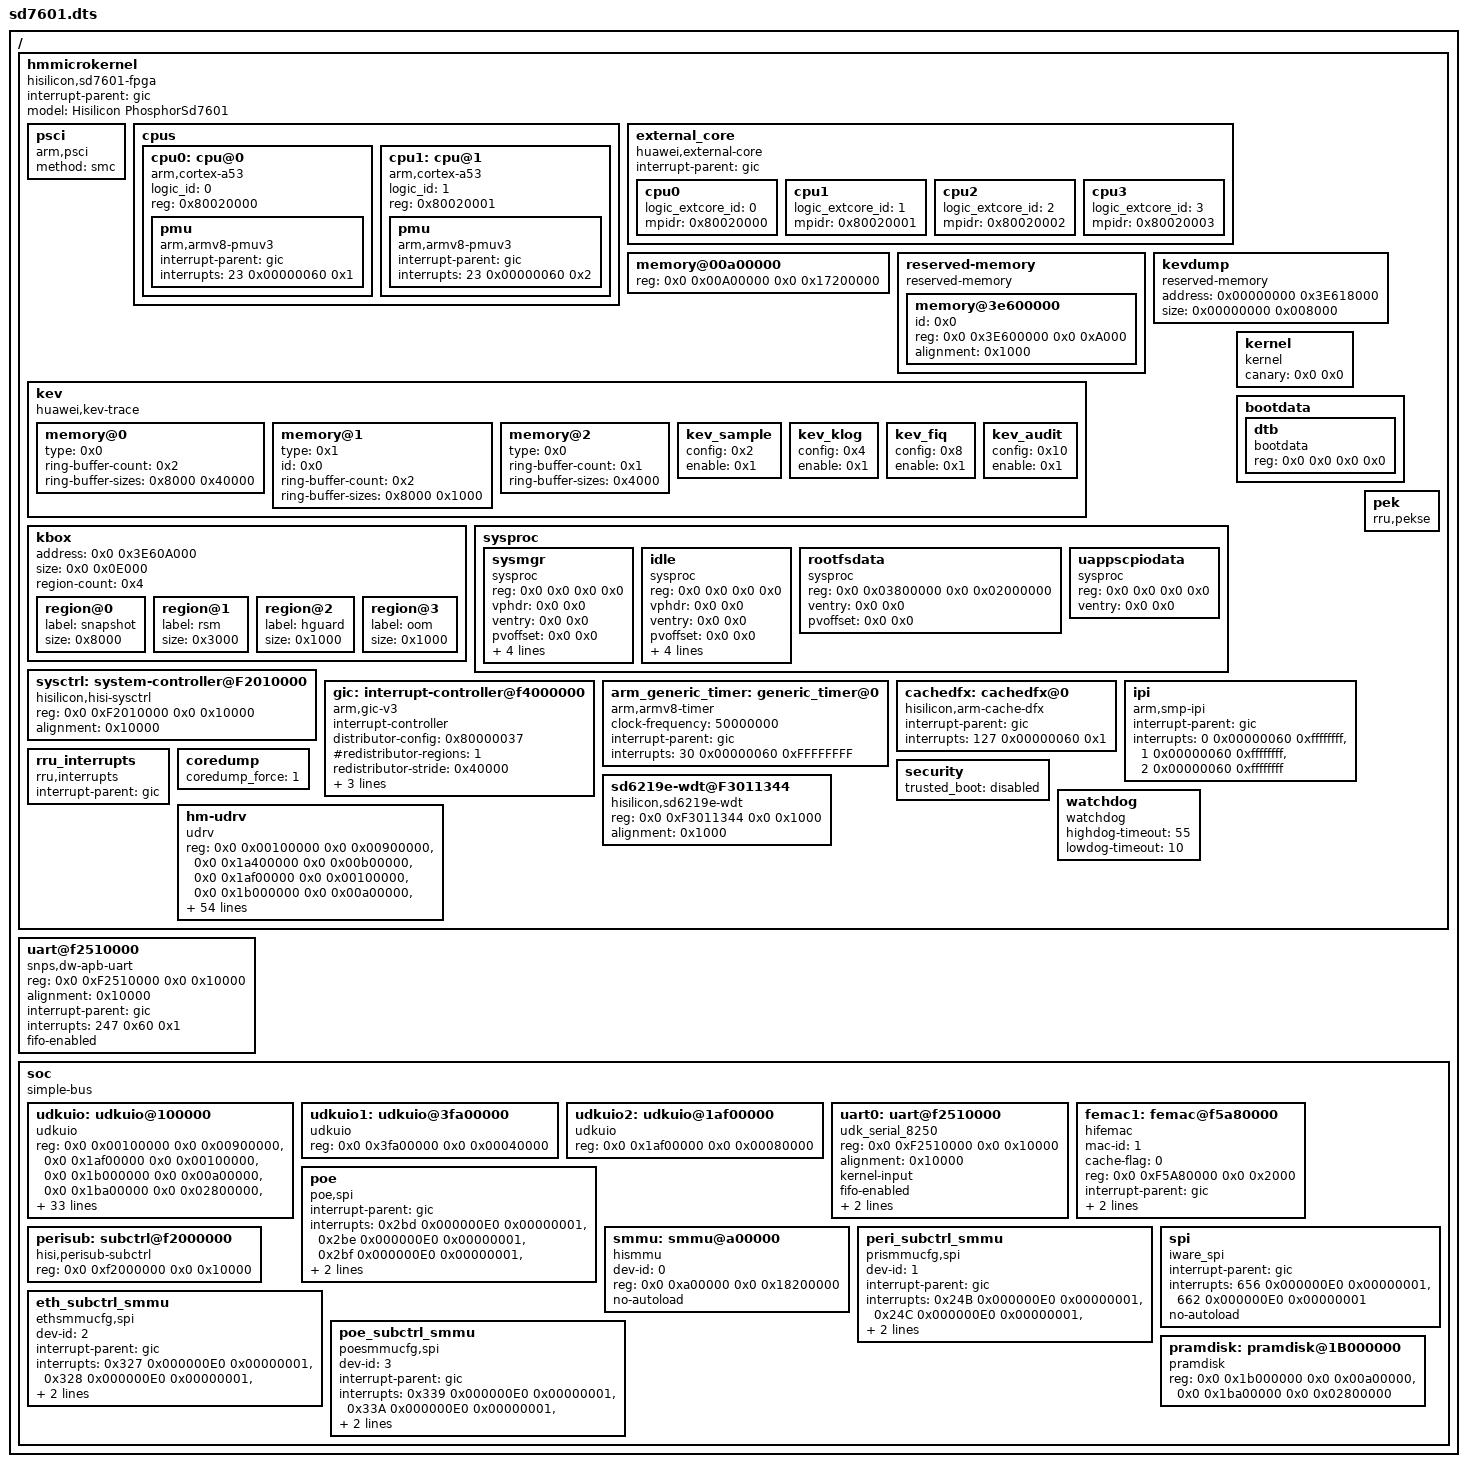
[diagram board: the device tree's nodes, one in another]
/*
 * Copyright (c) Huawei Technologies Co., Ltd. 2020-2021. All rights reserved.
 * Description: Device Tree file for TIANSHAN SD7601 BBL Board
 * Author: Huawei OS Kernel Lab
 * Create: Thu Sep 13 03:39:49 2020
 */

/dts-v1/;

/ {
	#address-cells = <2>;
	#size-cells = <2>;
	hmmicrokernel {
		#address-cells = <2>;
		#size-cells = <2>;
		interrupt-parent = <&gic>;

		model = "Hisilicon PhosphorSd7601";
		compatible = "hisilicon,sd7601-fpga", "hisilicon,hisi-sd7601";

		psci {
			compatible = "arm,psci";
			method = "smc";
		};

		cpus {
			#address-cells = <1>;
			#size-cells = <0>;

			cpu0: cpu@0 {
				compatible = "arm,cortex-a53", "arm,armv8";
				device_type = "cpu";
				logic_id = <0>;
				reg = <0x80020000>;
				pmu {
					compatible = "arm,armv8-pmuv3";
					interrupt-parent = <&gic>;
					/* PPI 23: PMUIRQ, level triggered, hwprio:0x60 */
					interrupts = <23 0x00000060 0x1>;
				};
			};
			cpu1: cpu@1 {
				compatible = "arm,cortex-a53", "arm,armv8";
				device_type = "cpu";
				logic_id = <1>;
				reg = <0x80020001>;
				pmu {
					compatible = "arm,armv8-pmuv3";
					interrupt-parent = <&gic>;
					/* PPI 23: PMUIRQ, level triggered, hwprio:0x60 */
					interrupts = <23 0x00000060 0x2>;
				};
			};
		};

		external_core {
			compatible = "huawei,external-core";

			interrupt-parent = <&gic>;

			cpu0 {
				logic_extcore_id = <0>;
				mpidr = <0x80020000>;
			};
			cpu1 {
				logic_extcore_id = <1>;
				mpidr = <0x80020001>;
			};
			cpu2 {
				logic_extcore_id = <2>;
				mpidr = <0x80020002>;
			};
			cpu3 {
				logic_extcore_id = <3>;
				mpidr = <0x80020003>;
			};
		};

		memory@00a00000 {
			device_type = "memory";
			reg = <0x0 0x00A00000 0x0 0x17200000>; /* OS kernel */
		};

		/* reserved memory for kev uses 0x3E600000-0x3E60A000 */
		reserved-memory {
			compatible = "reserved-memory";
			#address-cells = <2>;
			#size-cells = <2>;
			memory@3e600000 {
				id = <0x0>;
				reg = <0x0 0x3E600000 0x0 0xA000>;
				alignment = <0x1000>;
			};
		};

		/* kev uses 0x3E600000-0x3E60A000 */
		kev {
			compatible = "huawei,kev-trace";

			memory@0 {
				type = <0x0>;
				ring-buffer-count = <0x2>;
				/*
				 * ring buffer 0: 32K
				 * ring buffer 1: 256K
				 */
				ring-buffer-sizes = <0x8000 0x40000>;
			};

			memory@1 {
				type = <0x1>; /* reserved memory */
				id = <0x0>;
				ring-buffer-count = <0x2>;
				/*
				 * Only ring buffer DATA sizes. Memory head and ring
				 * buffer heads are not included.
				 * ring buffer 2: 32K(klog)
				 * ring buffer 3: 4K(fiq)
				 */
				ring-buffer-sizes = <0x8000 0x1000>;
			};

			memory@2 {
				type = <0x0>;
				ring-buffer-count = <0x1>;
				/*
				 * ring buffer 4: 16K(audit)
				 */
				ring-buffer-sizes = <0x4000>;
			};
			kev_sample {
				config = <0x2>;
				enable = <0x1>;
			};
			kev_klog {
				config = <0x4>;
				enable = <0x1>;
			};
			kev_fiq {
				config = <0x8>;
				enable = <0x1>;
			};
			kev_audit {
				config = <0x10>;
				enable = <0x1>;
			};
		};

		/* kbox uses 0x3E60A000-0x3E618000 */
		kbox {
			address = <0x0 0x3E60A000>;
			size = <0x0 0x0E000>;
			region-count= <0x4>;
			region@0 {
				label = "snapshot";
				size = <0x8000>;
			};
			region@1 {
				label = "rsm";
				size = <0x3000>;
			};
			region@2 {
				label = "hguard";
				size = <0x1000>;
			};
			region@3 {
				label = "oom";
				size = <0x1000>;
			};
		};

		/* kevdump uses 0x3E618000-0x3E620000 */
		kevdump {
			compatible = "reserved-memory";
			address = <0x00000000 0x3E618000>;
			size = <0x00000000 0x008000>;
		};

		sysproc {
			#address-cells = <2>;
			#size-cells = <2>;
			sysmgr {
				compatible = "sysproc", "sysmgr";
				/* filled by bootloader */
				reg      = <0x0 0x0 0x0 0x0>;
				vphdr    = <0x0 0x0>;
				ventry   = <0x0 0x0>;
				pvoffset = <0x0 0x0>;
				nphdrs   = <0>;
				stack_start = <0x0 0x0>;
				stack_end = <0x0 0x0>;
				canary = <0x0 0x0>;
			};
			idle {
				compatible = "sysproc", "idle";
				/* filled by bootloader */
				reg      = <0x0 0x0 0x0 0x0>;
				vphdr    = <0x0 0x0>;
				ventry   = <0x0 0x0>;
				pvoffset = <0x0 0x0>;
				nphdrs   = <0>;
				stack_start = <0x0 0x0>;
				stack_end = <0x0 0x0>;
				canary = <0x0 0x0>;
			};
			/* Describe board boot param rootfs in top level dts */
			rootfsdata {
				compatible = "sysproc", "rootfs";
				reg = <0x0 0x03800000 0x0 0x02000000>;
				ventry = <0x0 0x0>;
				/* filled by bootloader */
				pvoffset = <0x0 0x0>;
			};
			/*
			 * Describe uappscpio param in dts, which will be edited by elfloader_ng
			 * after uapps.cpio is loaded, provide for loading uapps
			 */
			uappscpiodata {
				compatible = "sysproc", "uappscpio";
				/* filled by bootloader */
				reg      = <0x0 0x0 0x0 0x0>;
				ventry   = <0x0 0x0>;
			};
		};

		kernel {
			compatible = "kernel";
			/* filled by bootloader */
			canary = <0x0 0x0>;
		};

		bootdata {
			#address-cells = <2>;
			#size-cells = <2>;
			dtb {
				compatible = "bootdata", "dtb";
				/* filled by bootloader */
				reg = <0x0 0x0 0x0 0x0>;
			};
		};

		sysctrl: system-controller@F2010000 {
			compatible = "hisilicon,hisi-sysctrl", "syscon";
			reg = <0x0 0xF2010000 0x0 0x10000>;
			alignment = <0x10000>;
		};

		gic: interrupt-controller@f4000000 {
			compatible = "arm,gic-v3";
			#interrupt-cells = <3>;
			interrupt-controller;

			/* Enable group 0, Group1NS, Group1S, ARE_NS, ARE_S,
			 * Split EOI and Deactive Mode */
			distributor-config = <0x80000037>;

			#redistributor-regions = <1>;
			redistributor-stride = <0x40000>;

			reg = <0x0 0xF4000000 0x0 0x10000>,  /* GICD */
			      <0x0 0xF4100000 0x0 0x400000>; /* GICR 16 CORE */
			alignment = <0x1000 0x1000>;
		};

		arm_generic_timer: generic_timer@0 {
			compatible = "arm,armv8-timer";
			clock-frequency = <50000000>;

			/* interrupt settings */
			interrupt-parent = <&gic>;

			/* PPI 30: Non-secure physical timer
			 * level triggered, hwprio:60 */
			interrupts = <30 0x00000060 0xFFFFFFFF>;
		};

		cachedfx: cachedfx@0 {
			compatible = "hisilicon,arm-cache-dfx";
			interrupt-parent = <&gic>;
			interrupts = <127 0x00000060 0x1>;
		};

		ipi {
			/* smp ipi */
			compatible = "arm,smp-ipi";

			interrupt-parent = <&gic>;

			/* interrupt settings:
			 * 1st cell: real hardware irq number
			 *     ARM recommendation: ID 0-7 for Non-Secure;
			 *                         ID 8-15 for Secure Interrupt
			 * 2nd cell: interrupt config
			 *     bit [27:26]: Group setting
			 *     bit [24]: Trigger Type
			 *     bit [23:8]: reserved
			 *     bit [7:0]: Priority
			 * 3rd cell: interrupt target config
			 *     support a maximum 8 CPUs.
			 */
			interrupts = <0 0x00000060 0xffffffff>, /* IPI_RESCHEDULE */
				     <1 0x00000060 0xffffffff>, /* IPI_CALL_FUNC */
				     <2 0x00000060 0xffffffff>; /* IPI_CPU_STOP */
		};

		/* using user-level irq dispatcher to manage all rru irqs */
		rru_interrupts {
			compatible = "rru,interrupts";
			interrupt-parent = <&gic>;
		};

		coredump {
			coredump_force = <1>;
		};
		security {
			trusted_boot = "disabled";
		};

		/* SD7601 CPU use same watchdog as sd6219e */
		sd6219e-wdt@F3011344 {
			compatible = "hisilicon,sd6219e-wdt";
			#address-cells = <2>;
			#size-cells = <2>;

			reg = <0x0 0xF3011344 0x0 0x1000>;
			alignment = <0x1000>;
		};

		watchdog {
			compatible = "watchdog";
			/* reserve 55ms for hguard to take over the watchdog */
			highdog-timeout = <55>;
			/* reserve 10ms for subcore to be pulled up*/
			lowdog-timeout = <10>;
		};

		hm-udrv {
			compatible = "udrv";
			reg = <0x0 0x00100000 0x0 0x00900000>, /* udkuio */
			      <0x0 0x1a400000 0x0 0x00b00000>, /* tee drv */
			      <0x0 0x1af00000 0x0 0x00100000>, /* libteec trace */
			      <0x0 0x1b000000 0x0 0x00a00000>, /* pramdisk idump*/
			      <0x0 0x1ba00000 0x0 0x02800000>, /* pramdisk lplog*/
			      <0x0 0x1e200000 0x0 0x00200000>, /* peklog */
			      <0x0 0x20400000 0x0 0x00400000>, /* femac + smmu */
			      <0x0 0x2da00000 0x0 0x0e800000>, /* udkuio */
			      <0x0 0x3c400000 0x0 0x00400000>, /* acc */
			      <0x0 0x3ce00000 0x0 0x00a00000>, /* udkuio */
			      <0x0 0x3d800000 0x0 0x00400000>, /* udkuio */
			      <0x0 0x3e200000 0x0 0x01e00000>, /* kbox */
			      <0x0 0x60000000 0x0 0x00004000>, /* udkuio */
			      <0x0 0xc0000000 0x0 0x20000000>, /* udkuio */
			      <0x0 0xf1000000 0x0 0x00100000>, /* udkuio */
			      <0x0 0xf12a0000 0x0 0x00001000>, /* udkuio */
			      <0x0 0xf1702000 0x0 0x00001000>, /* i2c */
			      <0x0 0xf1310000 0x0 0x00001000>, /* udkuio */
			      <0x0 0xf2000000 0x0 0x00100000>, /* spi, espi */
			      <0x0 0xf2140000 0x0 0x00240000>, /* udkuio */
			      <0x0 0xf23e0000 0x0 0x00040000>, /* i2c */
			      <0x0 0xf2400000 0x0 0x00001000>,
			      <0x0 0xf2410000 0x0 0x00001000>,
			      <0x0 0xf2430000 0x0 0x00020000>, /* spi */
			      <0x0 0xf2490000 0x0 0x00010000>, /* nor */
			      <0x0 0xf24a0000 0x0 0x00010000>, /* trng */
			      <0x0 0xf24e0000 0x0 0x00010000>, /* espi */
			      <0x0 0xf2510000 0x0 0x00010000>, /* uart */
			      <0x0 0xf2520000 0x0 0x00001000>,
			      <0x0 0xf2540000 0x0 0x00040000>, /* udkuio */
			      <0x0 0xf2548000 0x0 0x00001000>, /* gpio */
			      <0x0 0xf2558000 0x0 0x00001000>,
			      <0x0 0xf2568000 0x0 0x00001000>,
			      <0x0 0xf2578000 0x0 0x00001000>,
			      <0x0 0xf2588000 0x0 0x00001000>,
			      <0x0 0xf2598000 0x0 0x00001000>,
			      <0x0 0xf25A8000 0x0 0x00001000>,
			      <0x0 0xf25B8000 0x0 0x00001000>, /* gpio */
			      <0x0 0xf2700000 0x0 0x00024000>,
			      <0x0 0xf3000000 0x0 0x00100000>, /* spi */
			      <0x0 0xf5000000 0x0 0x00100000>, /* udkuio */
			      <0x0 0xf5200000 0x0 0x00020000>, /* udkuio */
			      <0x0 0xf5880000 0x0 0x00003000>,
			      <0x0 0xf5A80000 0x0 0x00002000>, /* femac0 */
			      <0x0 0xf5b80000 0x0 0x00010000>, /* spi */
			      <0x0 0xf5c00000 0x0 0x00010000>, /* spi */
			      <0x0 0xf7000000 0x0 0x00100000>, /* udkuio */
			      <0x0 0xfa000000 0x0 0x00b00000>, /* udkuio */
			      <0x0 0xfb000000 0x0 0x00a00000>, /* udkuio */
			      <0x0 0xfc000000 0x0 0x00100000>, /* espi */
			      <0x0 0xfd000000 0x0 0x01400000>, /* udkuio */
			      <0x0 0xfe400000 0x0 0x00400000>, /* udkuio */
			      <0x0 0xfe800000 0x0 0x00100000>, /* udkuio */
			      <0x0 0xff000000 0x0 0x01000000>, /* udkuio */
			      <0x6 0x00000000 0x0 0x10000000>, /* espi, SFC */
			      <0x6 0xc0000000 0x1 0x40000000>, /* SRE CP PA */
			      <0xA 0x01000000 0x0 0x02000000>,
			      <0xA 0x04000000 0x0 0x02000000>;
		};

		pek {
			compatible = "rru,pekse";
		};
	};

	/* For kernel uart driver */
	uart@f2510000 {
		compatible = "snps,dw-apb-uart", "arm,dw8250,uart";
		reg = <0x0 0xF2510000 0x0 0x10000>;
		alignment = <0x10000>;

		interrupt-parent = <&gic>;
		/* priority 2, level-triggered, target cpu 0 */
		interrupts = <247 0x60 0x1>;
		/* enable fifo */
		fifo-enabled;
	};

	soc {
		compatible = "simple-bus";
		#address-cells = <2>;
		#size-cells = <2>;
		ranges;

		udkuio: udkuio@100000 {
			compatible = "udkuio";
			reg = <0x0 0x00100000 0x0 0x00900000>,
			      <0x0 0x1af00000 0x0 0x00100000>,
			      <0x0 0x1b000000 0x0 0x00a00000>, /* pramdisk idump*/
			      <0x0 0x1ba00000 0x0 0x02800000>, /* pramdisk lplog*/
			      <0x0 0x1e200000 0x0 0x00200000>, /* peklog */
			      <0x0 0x20400000 0x0 0x00400000>, /* femac + smmu */
			      <0x0 0x2da00000 0x0 0x0e800000>,
			      <0x0 0x3ce00000 0x0 0x00a00000>,
			      <0x0 0x3d800000 0x0 0x00400000>,
			      <0x0 0x3e200000 0x0 0x01e00000>, /* kbox */
			      <0x0 0x60000000 0x0 0x00004000>,
			      <0x0 0xc0000000 0x0 0x20000000>,
			      <0x0 0xf1000000 0x0 0x00100000>,
			      <0x0 0xf12a0000 0x0 0x00001000>,
			      <0x0 0xf1310000 0x0 0x00001000>,
			      <0x0 0xf2000000 0x0 0x00100000>,
			      <0x0 0xf2140000 0x0 0x00240000>,
			      <0x0 0xf24a0000 0x0 0x00010000>, /* trng */
			      <0x0 0xf24e0000 0x0 0x00010000>, /* espi */
			      <0x0 0xf2540000 0x0 0x00040000>,
			      <0x0 0xf3000000 0x0 0x00100000>,
			      <0x0 0xf5000000 0x0 0x00100000>,
			      <0x0 0xf5200000 0x0 0x00020000>,
			      <0x0 0xf7000000 0x0 0x00100000>,
			      <0x0 0xfa000000 0x0 0x00b00000>,
			      <0x0 0xfb000000 0x0 0x00a00000>,
			      <0x0 0xfc000000 0x0 0x00100000>,
			      <0x0 0xfd000000 0x0 0x01400000>,
			      <0x0 0xfe400000 0x0 0x00400000>,
			      <0x0 0xfe800000 0x0 0x00100000>,
			      <0x0 0xff000000 0x0 0x01000000>,
			      <0x6 0x00000000 0x0 0x01000000>, /* espi, SFC */
			      <0x6 0x01000000 0x0 0x02000000>, /* espi, SFC */
			      <0x6 0x03000000 0x0 0x0d000000>, /* espi, SFC */
			      <0x6 0xc0000000 0x1 0x40000000>, /* SRE CP PA */
			      <0xA 0x01000000 0x0 0x02000000>,
			      <0xA 0x04000000 0x0 0x02000000>;
		};

		udkuio1: udkuio@3fa00000 {
			compatible = "udkuio";
			reg = <0x0 0x3fa00000 0x0 0x00040000>;    /* sRoCE SHM */
		};

		udkuio2: udkuio@1af00000 {
			compatible = "udkuio";
			reg = <0x0 0x1af00000 0x0 0x00080000>;   /* libteec SHM */
		};

		uart0: uart@f2510000 {
			compatible = "udk_serial_8250";
			reg = <0x0 0xF2510000 0x0 0x10000>;
			alignment = <0x10000>;

			kernel-input;
			/* enable fifo */
			fifo-enabled;
			clock_frequency = <187500000>;
			no-autoload;
		};

		femac1: femac@f5a80000 {
			compatible = "hifemac";
			mac-id = <1>;
			cache-flag = <0>;
			reg = <0x0 0xF5A80000 0x0 0x2000>;
			interrupt-parent = <&gic>;
			interrupts = <627 0x000000E0 0x00000001>;
			no-autoload;
		};

		poe {
			compatible = "poe,spi";
			interrupt-parent = <&gic>;
			interrupts = <0x2bd 0x000000E0 0x00000001>,
				     <0x2be 0x000000E0 0x00000001>,
				     <0x2bf 0x000000E0 0x00000001>,
				     <0x2c0 0x000000E0 0x00000001>;
			no-autoload;
		};

		perisub:subctrl@f2000000 {
			compatible = "hisi,perisub-subctrl";
			reg = <0x0 0xf2000000 0x0 0x10000>;
		};

		smmu:smmu@a00000 {
			compatible = "hismmu";
			dev-id = <0>;
			reg = <0x0 0xa00000 0x0 0x18200000>;
			no-autoload;
		};

		peri_subctrl_smmu {
			compatible = "prismmucfg,spi";
			dev-id = <1>;
			interrupt-parent = <&gic>;
			interrupts = <0x24B 0x000000E0 0x00000001>,
				     <0x24C 0x000000E0 0x00000001>,
				     <0x24D 0x000000E0 0x00000001>;
			no-autoload;
		};

		eth_subctrl_smmu {
			compatible = "ethsmmucfg,spi";
			dev-id = <2>;
			interrupt-parent = <&gic>;
			interrupts = <0x327 0x000000E0 0x00000001>,
				     <0x328 0x000000E0 0x00000001>,
				     <0x329 0x000000E0 0x00000001>;
			no-autoload;
		};

		poe_subctrl_smmu {
			compatible = "poesmmucfg,spi";
			dev-id = <3>;
			interrupt-parent = <&gic>;
			interrupts = <0x339 0x000000E0 0x00000001>,
				     <0x33A 0x000000E0 0x00000001>,
				     <0x33B 0x000000E0 0x00000001>;
			no-autoload;
		};

		spi {
			compatible = "iware_spi";
			interrupt-parent = <&gic>;
			interrupts = <656 0x000000E0 0x00000001>,
				     <662 0x000000E0 0x00000001>;
			no-autoload;
		};

		pramdisk: pramdisk@1B000000 {
			compatible = "pramdisk";
			reg = <0x0 0x1b000000 0x0 0x00a00000>,
			      <0x0 0x1ba00000 0x0 0x02800000>;
		};
	};
};
